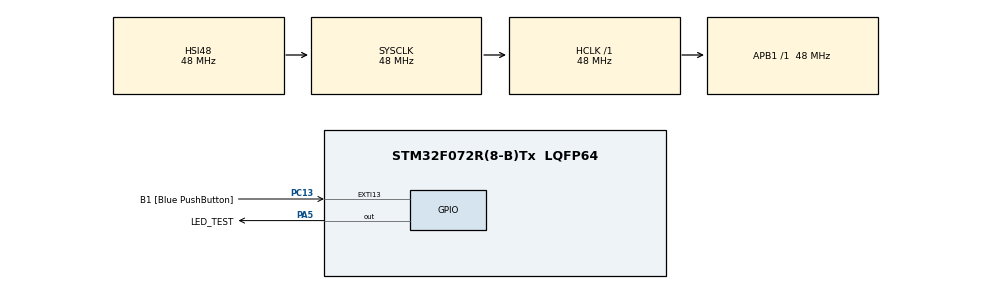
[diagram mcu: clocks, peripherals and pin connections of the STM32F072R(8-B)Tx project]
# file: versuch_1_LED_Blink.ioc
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Mcu.Family=STM32F0
Mcu.Name=STM32F072R(8-B)Tx
Mcu.Package=LQFP64
PA13.GPIO_Label=TMS
PA13.Mode=Serial_Wire
PA13.Signal=SYS_SWDIO
PA14.GPIO_Label=TCK
PA14.Mode=Serial_Wire
PA14.Signal=SYS_SWCLK
PA3.Signal=USART2_RX
PA5.GPIO_Label=LED_TEST
PA5.GPIO_Speed=GPIO_SPEED_FREQ_HIGH
PA5.Signal=GPIO_Output
PC13.GPIO_Label=B1 [Blue PushButton]
PC13.GPIO_ModeDefaultEXTI=GPIO_MODE_IT_FALLING
PC13.Signal=GPXTI13
PC14-OSC32_IN.Mode=LSE-External-Oscillator
PC14-OSC32_IN.Signal=RCC_OSC32_IN
PC15-OSC32_OUT.Mode=LSE-External-Oscillator
PC15-OSC32_OUT.Signal=RCC_OSC32_OUT
PF0-OSC_IN.Mode=HSE-External-Clock-Source
PF0-OSC_IN.Signal=RCC_OSC_IN
PF1-OSC_OUT.Signal=RCC_OSC_OUT
ProjectManager.HeapSize=0x200
ProjectManager.StackSize=0x400
ProjectManager.TargetToolchain=STM32CubeIDE
RCC.AHBFreq_Value=48000000
RCC.APB1Freq_Value=48000000
RCC.APB1TimFreq_Value=48000000
RCC.FLatency-AdvancedSettings=FLASH_LATENCY_1
RCC.HCLKFreq_Value=48000000
RCC.PLLDivider=RCC_PREDIV_DIV2
RCC.PLLMUL=RCC_PLL_MUL12
RCC.PREFETCH_ENABLE-AdvancedSettings=1
RCC.SYSCLKFreq_VALUE=48000000
RCC.SYSCLKSource=RCC_SYSCLKSOURCE_HSI48
board=NUCLEO-F072RB

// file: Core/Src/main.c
/* USER CODE BEGIN Header */
/**
  ******************************************************************************
  * @file           : main.c
  * @brief          : Main program body
  ******************************************************************************
  * @attention
  *
  * Copyright (c) 2026 STMicroelectronics.
  * All rights reserved.
  *
  * This software is licensed under terms that can be found in the LICENSE file
  * in the root directory of this software component.
  * If no LICENSE file comes with this software, it is provided AS-IS.
  *
  ******************************************************************************
  */
/* USER CODE END Header */
#include "main.h"

void SystemClock_Config(void);
static void MX_GPIO_Init(void);

int main(void)
{

  /* MCU Configuration--------------------------------------------------------*/

  /* Reset of all peripherals, Initializes the Flash interface and the Systick. */
  HAL_Init();

  /* Configure the system clock */
  SystemClock_Config();

  /* Initialize all configured peripherals */
  MX_GPIO_Init();

  /* Infinite loop */
  while (1)
  {
    /* USER CODE BEGIN 3 */

	  HAL_GPIO_TogglePin(LED_TEST_GPIO_Port, LED_TEST_Pin) ;
	  HAL_Delay(500) ;

	  /*
	  HAL_GPIO_WritePin(LED_TEST_GPIO_Port, LED_TEST_Pin, GPIO_PIN_SET);
	  HAL_Delay(1000) ;
	  HAL_GPIO_WritePin(LED_TEST_GPIO_Port, LED_TEST_Pin, GPIO_PIN_RESET);
	  HAL_Delay(1000) ;
	  */

  }
  /* USER CODE END 3 */
}

void SystemClock_Config(void)
{
  RCC_OscInitTypeDef RCC_OscInitStruct = {0};
  RCC_ClkInitTypeDef RCC_ClkInitStruct = {0};

  /** Initializes the RCC Oscillators according to the specified parameters
  * in the RCC_OscInitTypeDef structure.
  */
  RCC_OscInitStruct.OscillatorType = RCC_OSCILLATORTYPE_HSI48;
  RCC_OscInitStruct.HSI48State = RCC_HSI48_ON;
  RCC_OscInitStruct.PLL.PLLState = RCC_PLL_NONE;
  if (HAL_RCC_OscConfig(&RCC_OscInitStruct) != HAL_OK)
  {
    Error_Handler();
  }

  /** Initializes the CPU, AHB and APB buses clocks
  */
  RCC_ClkInitStruct.ClockType = RCC_CLOCKTYPE_HCLK|RCC_CLOCKTYPE_SYSCLK
                              |RCC_CLOCKTYPE_PCLK1;
  RCC_ClkInitStruct.SYSCLKSource = RCC_SYSCLKSOURCE_HSI48;
  RCC_ClkInitStruct.AHBCLKDivider = RCC_SYSCLK_DIV1;
  RCC_ClkInitStruct.APB1CLKDivider = RCC_HCLK_DIV1;

  if (HAL_RCC_ClockConfig(&RCC_ClkInitStruct, FLASH_LATENCY_1) != HAL_OK)
  {
    Error_Handler();
  }
}

static void MX_GPIO_Init(void)
{
  GPIO_InitTypeDef GPIO_InitStruct = {0};

  /* GPIO Ports Clock Enable */
  __HAL_RCC_GPIOC_CLK_ENABLE();
  __HAL_RCC_GPIOF_CLK_ENABLE();
  __HAL_RCC_GPIOA_CLK_ENABLE();

  /*Configure GPIO pin Output Level */
  HAL_GPIO_WritePin(LED_TEST_GPIO_Port, LED_TEST_Pin, GPIO_PIN_RESET);

  /*Configure GPIO pin : B1_Pin */
  GPIO_InitStruct.Pin = B1_Pin;
  GPIO_InitStruct.Mode = GPIO_MODE_IT_FALLING;
  GPIO_InitStruct.Pull = GPIO_NOPULL;
  HAL_GPIO_Init(B1_GPIO_Port, &GPIO_InitStruct);

  /*Configure GPIO pin : PA3 */
  GPIO_InitStruct.Pin = GPIO_PIN_3;
  GPIO_InitStruct.Mode = GPIO_MODE_AF_PP;
  GPIO_InitStruct.Pull = GPIO_NOPULL;
  GPIO_InitStruct.Speed = GPIO_SPEED_FREQ_HIGH;
  GPIO_InitStruct.Alternate = GPIO_AF1_USART2;
  HAL_GPIO_Init(GPIOA, &GPIO_InitStruct);

  /*Configure GPIO pin : LED_TEST_Pin */
  GPIO_InitStruct.Pin = LED_TEST_Pin;
  GPIO_InitStruct.Mode = GPIO_MODE_OUTPUT_PP;
  GPIO_InitStruct.Pull = GPIO_NOPULL;
  GPIO_InitStruct.Speed = GPIO_SPEED_FREQ_HIGH;
  HAL_GPIO_Init(LED_TEST_GPIO_Port, &GPIO_InitStruct);

}

void Error_Handler(void)
{
  __disable_irq();
  while (1)
  {
  }
}
